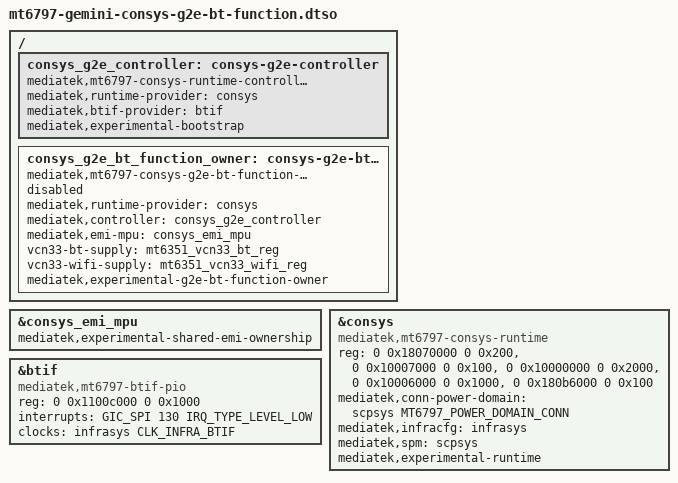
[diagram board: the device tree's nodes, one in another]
// SPDX-License-Identifier: GPL-2.0-only
/* One-shot G2e BT PALDO/FUNC_CTRL proof; a successor, never a stackable node. */
/dts-v1/;
/plugin/;

#include <dt-bindings/clock/mt6797-clk.h>
#include <dt-bindings/interrupt-controller/arm-gic.h>
#include <dt-bindings/power/mt6797-power.h>

/ {
	fragment@0 { target = <&consys_emi_mpu>; __overlay__ {
		mediatek,experimental-shared-emi-ownership; status = "okay"; }; };
	fragment@1 { target = <&consys>; #address-cells = <2>; #size-cells = <2>;
		__overlay__ {
			compatible = "mediatek,mt6797-consys-runtime";
			reg = <0 0x18070000 0 0x200>, <0 0x10007000 0 0x100>,
			      <0 0x10000000 0 0x2000>, <0 0x10006000 0 0x1000>,
			      <0 0x180b6000 0 0x100>;
			reg-names = "mcu", "ap-rgu", "topckgen", "spm", "afe";
			mediatek,conn-power-domain = <&scpsys MT6797_POWER_DOMAIN_CONN>;
			mediatek,infracfg = <&infrasys>; mediatek,spm = <&scpsys>;
			mediatek,experimental-runtime; status = "okay"; }; };
	fragment@2 { target = <&btif>; #address-cells = <2>; #size-cells = <2>;
		interrupt-parent = <&sysirq>; __overlay__ {
			compatible = "mediatek,mt6797-btif-pio";
			reg = <0 0x1100c000 0 0x1000>;
			interrupts = <GIC_SPI 130 IRQ_TYPE_LEVEL_LOW>;
			clocks = <&infrasys CLK_INFRA_BTIF>; clock-names = "btifc";
			/delete-property/ reg-shift; /delete-property/ reg-io-width;
			status = "okay"; }; };
	fragment@3 { target-path = "/"; __overlay__ {
		consys_g2e_controller: consys-g2e-controller {
			compatible = "mediatek,mt6797-consys-runtime-controller";
			mediatek,runtime-provider = <&consys>; mediatek,btif-provider = <&btif>;
			mediatek,experimental-bootstrap; status = "okay"; };
		consys_g2e_bt_function_owner: consys-g2e-bt-function-owner {
			compatible = "mediatek,mt6797-consys-g2e-bt-function-owner";
			mediatek,runtime-provider = <&consys>; mediatek,controller = <&consys_g2e_controller>;
			mediatek,emi-mpu = <&consys_emi_mpu>;
			vcn33-bt-supply = <&mt6351_vcn33_bt_reg>;
			vcn33-wifi-supply = <&mt6351_vcn33_wifi_reg>;
			mediatek,experimental-g2e-bt-function-owner; status = "disabled"; };
	}; };
};
